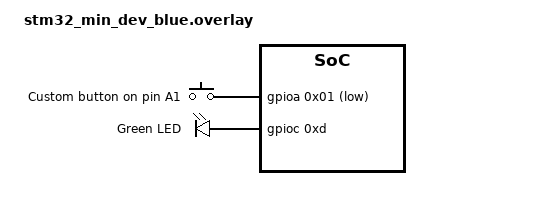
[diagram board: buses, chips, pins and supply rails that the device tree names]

/ {
	buttons {
		compatible = "gpio-keys";
		button1: button-a1 {
			gpios = <&gpioa 0x01 (GPIO_PULL_UP | GPIO_ACTIVE_LOW)>;
			label = "Custom button on pin A1";
		};
	};
	leds{
		compatible = "gpio-leds";

		green_led:led-c13{
			gpios = <&gpioc 0xd GPIO_ACTIVE_HIGH>;
			label = "Green LED";
		};
	};
};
